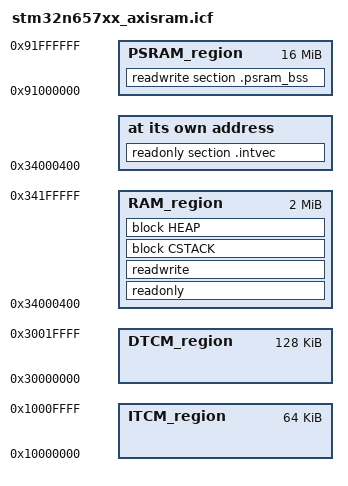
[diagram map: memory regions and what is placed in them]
/*###ICF### Section handled by ICF editor, don't touch! ****/
/*-Editor annotation file-*/
/* IcfEditorFile="$TOOLKIT_DIR$\config\ide\IcfEditor\cortex_v1_0.xml" */
/*-Specials-*/
define symbol __ICFEDIT_intvec_start__ = 0x34000400;
/*-Memory Regions-*/
define symbol __ICFEDIT_region_RAM_start__ = 0x34000400;
define symbol __ICFEDIT_region_RAM_end__   = 0x341fffff;
/*-Sizes-*/
define symbol __ICFEDIT_size_cstack__ = 0x1000;
define symbol __ICFEDIT_size_heap__   = 0x200;
/**** End of ICF editor section. ###ICF###*/

define symbol __region_ITCM_start__  = 0x10000000;
define symbol __region_ITCM_end__    = 0x1000FFFF;
define symbol __region_DTCM_start__  = 0x30000000;
define symbol __region_DTCM_end__    = 0x3001FFFF;

define memory mem with size = 4G;
define region RAM_region      = mem:[from __ICFEDIT_region_RAM_start__ to __ICFEDIT_region_RAM_end__];
define region ITCM_region     = mem:[from __region_ITCM_start__ to __region_ITCM_end__];
define region DTCM_region     = mem:[from __region_DTCM_start__ to __region_DTCM_end__];
define region PSRAM_region    = mem:[from 0x91000000 to 0x91FFFFFF];

define block CSTACK    with alignment = 8, size = __ICFEDIT_size_cstack__   { };
define block HEAP      with alignment = 8, size = __ICFEDIT_size_heap__     { };

initialize by copy { readwrite };
do not initialize  { section .noinit };
do not initialize  { section .uncached_bss };
do not initialize  { section .psram_bss };

place at address mem:__ICFEDIT_intvec_start__ { readonly section .intvec };

place in RAM_region   { readonly, readwrite,
                        block CSTACK, block HEAP };
place in PSRAM_region { readwrite section .psram_bss };

build for ram;
